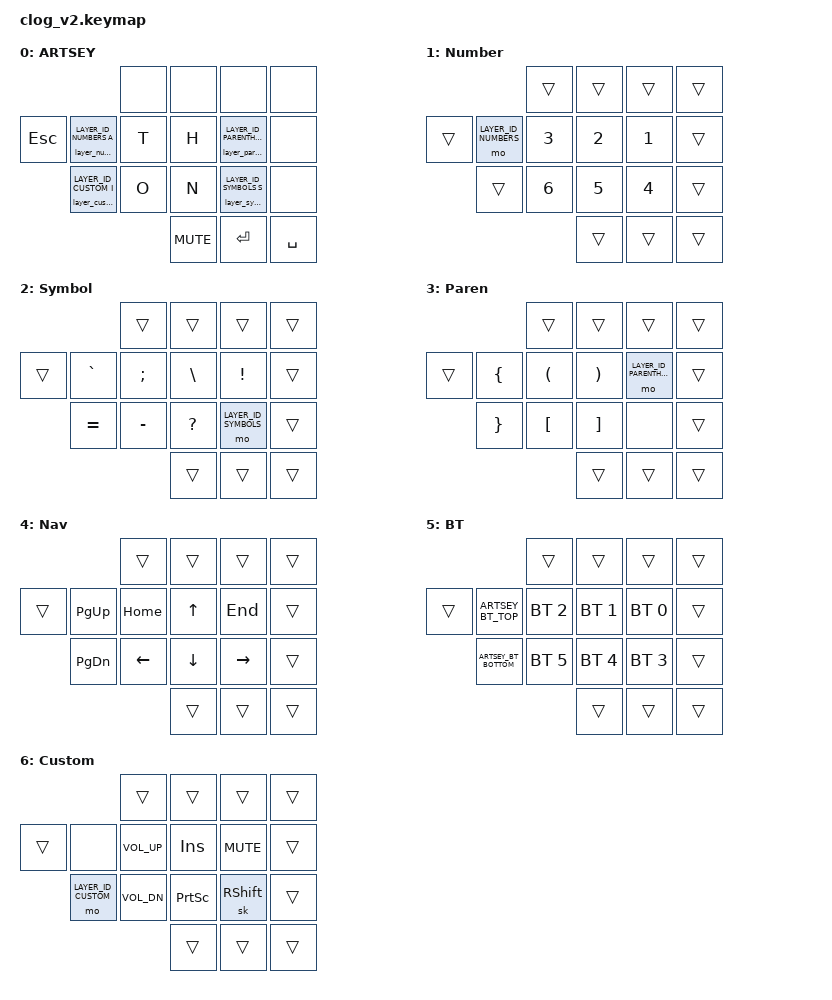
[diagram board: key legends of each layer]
#include <behaviors.dtsi>
#include <dt-bindings/zmk/keys.h>
#include <dt-bindings/zmk/bt.h>

#define KEY_E 8
#define KEY_H 7
#define KEY_T 6
#define KEY_A 5
#define KEY_S 13
#define KEY_N 12
#define KEY_O 11
#define KEY_I 10

#include "artsey.dtsi"

/ {
    keymap {
        compatible = "zmk,keymap";
        base {
            label = "ARTSEY";
            bindings = <
                                                         &none &none       &none                                              &none
            &kp ESC &layer_numbers_kp LAYER_ID_NUMBERS A &kp T &kp H       &layer_parentheticals_kp LAYER_ID_PARENTHETICALS E &none
                    &layer_custom_kp LAYER_ID_CUSTOM I   &kp O &kp N       &layer_symbols_kp LAYER_ID_SYMBOLS S               &none
                                                               &kp C_MUTE  &kp ENTER                                          &kp SPC
            >;

			sensor-bindings = <&inc_dec_kp PG_DN PG_UP>;
        };
		numbers {
			label = "Number";
			bindings = <
				                         &trans &trans &trans &trans
			&trans &mo LAYER_ID_NUMBERS  &kp N3 &kp N2 &kp N1 &trans
				   &trans                &kp N6 &kp N5 &kp N4 &trans
                                                &trans &trans &trans
				
			>;
		};
		symbols {
			label = "Symbol";
			bindings = <
				             &trans    &trans    &trans               &trans
			&trans &kp GRAVE &kp SEMI  &kp BSLH  &kp EXCL             &trans
				   &kp EQUAL &kp MINUS &kp QMARK &mo LAYER_ID_SYMBOLS &trans
                                       &trans    &trans               &trans
			>;
		};
		parentheticals {
			label = "Paren";
			bindings = <
			                &trans   &trans   &trans                      &trans
			&trans &kp LBRC &kp LPAR &kp RPAR &mo LAYER_ID_PARENTHETICALS &trans
			       &kp RBRC &kp LBKT &kp RBKT &none                       &trans
                                     &trans   &trans                      &trans
			>;
		};
		navigation {
			label = "Nav";
			bindings = <
				             &trans   &trans   &trans    &trans
			&trans &kp PG_UP &kp HOME &kp UP   &kp END   &trans
				   &kp PG_DN &kp LEFT &kp DOWN &kp RIGHT &trans
				                      &trans   &trans    &trans
			>;
		};
		bt {
			label = "BT";
			bindings = <
				                    &trans       &trans       &trans       &trans
			&trans ARTSEY_BT_TOP    &bt BT_SEL 2 &bt BT_SEL 1 &bt BT_SEL 0 &trans
				   ARTSEY_BT_BOTTOM &bt BT_SEL 5 &bt BT_SEL 4 &bt BT_SEL 3 &trans
				                                 &trans       &trans       &trans
			>;
		};
        custom {                                                       \
			label = "Custom";                                          \
			bindings = <
				                       &trans        &trans    &trans     &trans                                          \
			&trans &none               &kp C_VOL_UP  &kp INS   &kp C_MUTE &trans
				   &mo LAYER_ID_CUSTOM &kp C_VOL_DN  &kp PSCRN &sk RSHFT  &trans
				                                 &trans       &trans       &trans
			>;
		};
	};
};

